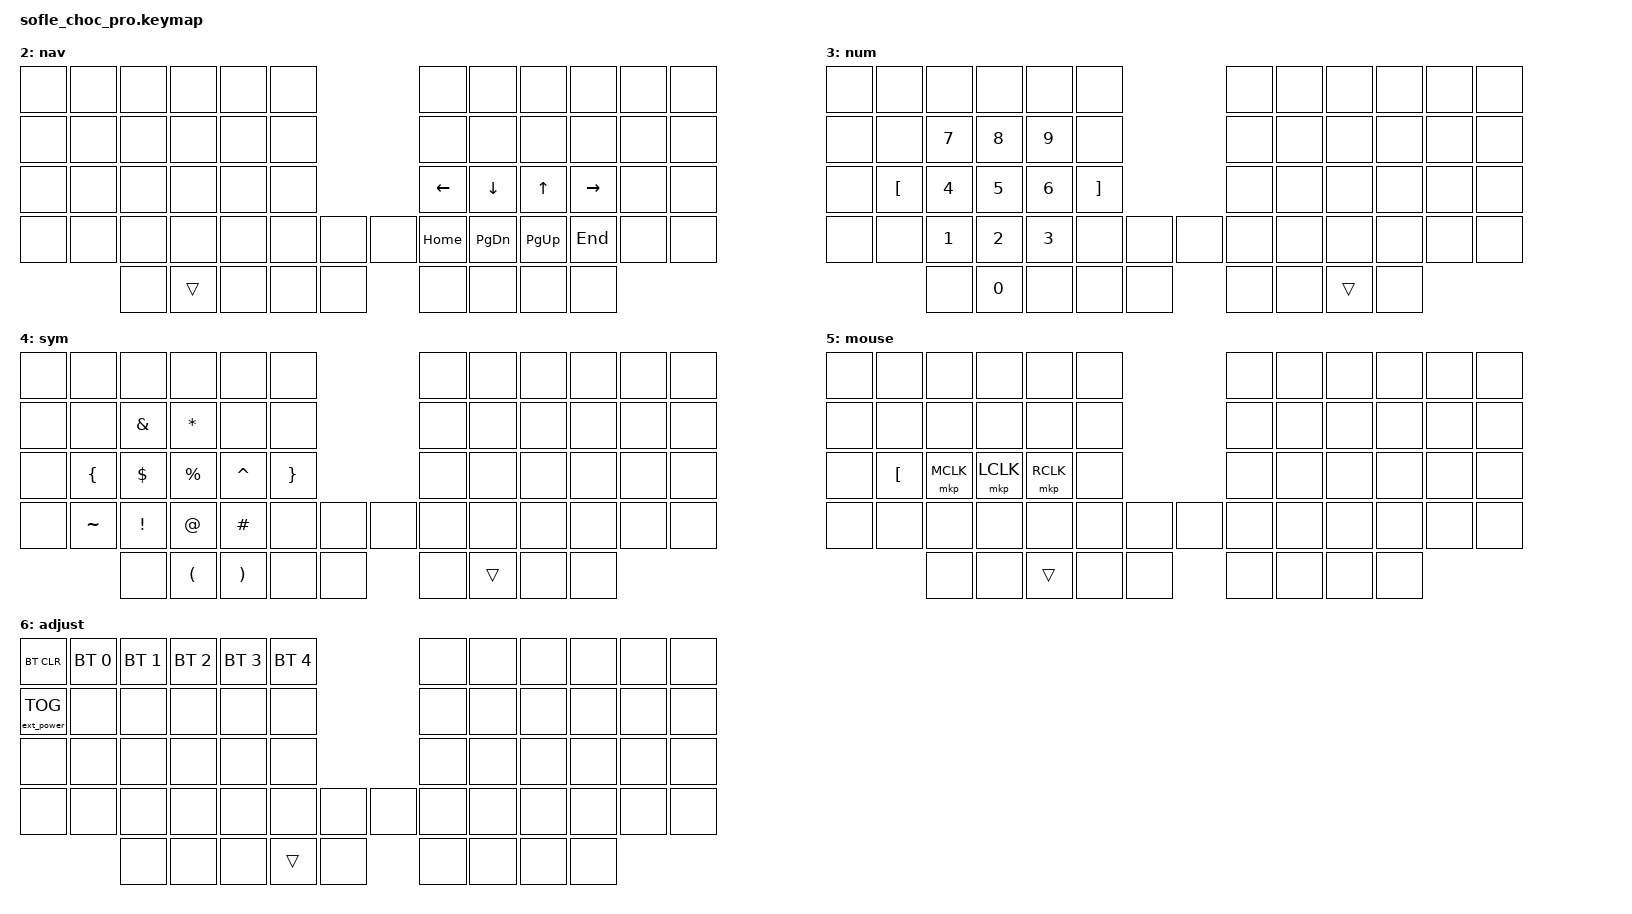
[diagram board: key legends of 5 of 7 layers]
/*
 * Sofle Choc Pro BT — ZMK Keymap
 * Exact port of QMK Dilemma keymap (casuanoob / 0xcharly)
 * Board: sofle_choc_pro_left / sofle_choc_pro_right + Prospector dongle
 *
 * Matrix: 14 columns × 5 rows = 60 keys
 *
 * Key position map (0-indexed, sequential):
 *  0  1  2  3  4  5              6  7  8  9 10 11   ← row 0 (12 keys)
 * 12 13 14 15 16 17             18 19 20 21 22 23   ← row 1 (12 keys)
 * 24 25 26 27 28 29             30 31 32 33 34 35   ← row 2 / home row (12 keys)
 * 36 37 38 39 40 41  42  43  44 45 46 47 48 49      ← row 3 (14 keys, 42+43 = center)
 *          50 51 52 53 54     55 56 57 58 59         ← row 4 / thumbs (10 keys)
 *
 * Home row positions:
 *   Left:  A=25  S=26  D=27  F=28
 *   Right: J=31  K=32  L=33  ;=34
 *
 * Combos (position-based, not keycode-based like QMK):
 *   D+F  = {27, 28} → Escape
 *   J+K  = {31, 32} → Enter
 *   F+J  = {28, 31} → CapsLock
 *
 * Thumb row (left side):  50=unused  51=NAV/BSPC  52=MOUSE/TAB  53=ADJUST  54=extra-key
 * Thumb row (right side): 55=extra-key  56=unused  57=SYM/ENT  58=NUM/SPC  59=→WIN/→MAC
 *
 * Layers:
 *   0 BASE    — Mac default, GACS home row mods
 *   1 BASEW   — Win default, SCAG home row mods
 *   2 NAV     — arrows, home/end/pgup/pgdn  (hold BSPC)
 *   3 NUM     — numpad                      (hold SPC)
 *   4 SYM     — symbols                    (hold ENT)
 *   5 MOUSE   — mouse buttons              (hold TAB)
 *   6 ADJUST  — BT management + RGB controls  (hold ADJUST thumb)
 *
 * QMK → ZMK notes:
 *   HYPR_T(KC_NO) → &trans (effectively a no-op)
 *   PT = LT(POINTER, KC_NO) → &mo ADJUST (tap = none, layer renamed to ADJUST)
 *   DPI_MOD / SNIPING / DRGSCRL → &none (Sofle has no trackball)
 *   EE_CLR → &bt BT_CLR
 *   QK_BOOT → &bootloader
 *   MS_BTNx → &mkp (ZMK pointing)
 *   Encoder keys (RC(3,6) RC(3,7)) kept as &none on non-media layers,
 *   assigned C_MUTE / C_PP on base layers to match original QMK encoder positions.
 */

#include <behaviors.dtsi>
#include <dt-bindings/zmk/keys.h>
#include <dt-bindings/zmk/bt.h>
#include <dt-bindings/zmk/mouse.h>
#include <dt-bindings/zmk/ext_power.h>

#define BASE    0
#define BASEW   1
#define NAV     2
#define NUM     3
#define SYM     4
#define MOUSE   5
#define ADJUST  6

// Key position groups for hold-trigger-key-positions
// Used to make HRMs directional: left HRMs only trigger with right-hand keys and vice versa
// Sofle Choc Pro 60-key matrix (0-indexed):
//  0  1  2  3  4  5          6  7  8  9 10 11   row 0
// 12 13 14 15 16 17         18 19 20 21 22 23   row 1
// 24 25 26 27 28 29         30 31 32 33 34 35   row 2
// 36 37 38 39 40 41  42 43  44 45 46 47 48 49   row 3
//          50 51 52 53 54   55 56 57 58 59       row 4
#define KEYS_L  0  1  2  3  4  5  12 13 14 15 16 17  24 25 26 27 28 29  36 37 38 39 40 41
#define KEYS_R  6  7  8  9 10 11  18 19 20 21 22 23  30 31 32 33 34 35  44 45 46 47 48 49
#define THUMBS 50 51 52 53 54 55 56 57 58 59
#define HYPER LS(LC(LA(LGUI)))

/ {
    // ─── Combos ───────────────────────────────────────────────────────────────
    combos {
        compatible = "zmk,combos";

        combo_esc {
            timeout-ms = <50>;
            key-positions = <27 28>;
            bindings = <&kp ESC>;
            layers = <BASE BASEW>;
        };
        combo_enter {
            timeout-ms = <50>;
            key-positions = <31 32>;
            bindings = <&kp ENTER>;
            layers = <BASE BASEW>;
        };
        combo_caps {
            timeout-ms = <50>;
            key-positions = <28 31>;
            bindings = <&kp CAPS>;
            layers = <BASE BASEW>;
        };
    };

    // ─── Macros ───────────────────────────────────────────────────────────────
    macros {
        mac_cut: mac_cut {
            compatible = "zmk,behavior-macro";
            #binding-cells = <0>;
            bindings = <&macro_press &kp LGUI>,
                       <&macro_tap &kp X>,
                       <&macro_release &kp LGUI>;
        };
        mac_copy: mac_copy {
            compatible = "zmk,behavior-macro";
            #binding-cells = <0>;
            bindings = <&macro_press &kp LGUI>,
                       <&macro_tap &kp C>,
                       <&macro_release &kp LGUI>;
        };
        mac_paste: mac_paste {
            compatible = "zmk,behavior-macro";
            #binding-cells = <0>;
            bindings = <&macro_press &kp LGUI>,
                       <&macro_tap &kp V>,
                       <&macro_release &kp LGUI>;
        };
        win_cut: win_cut {
            compatible = "zmk,behavior-macro";
            #binding-cells = <0>;
            bindings = <&macro_press &kp LCTRL>,
                       <&macro_tap &kp X>,
                       <&macro_release &kp LCTRL>;
        };
        win_copy: win_copy {
            compatible = "zmk,behavior-macro";
            #binding-cells = <0>;
            bindings = <&macro_press &kp LCTRL>,
                       <&macro_tap &kp C>,
                       <&macro_release &kp LCTRL>;
        };
        win_paste: win_paste {
            compatible = "zmk,behavior-macro";
            #binding-cells = <0>;
            bindings = <&macro_press &kp LCTRL>,
                       <&macro_tap &kp V>,
                       <&macro_release &kp LCTRL>;
        };
    };

    // ─── Behaviors ────────────────────────────────────────────────────────────
    behaviors {
        // Home row mods — directional, with prior-idle guard
        // Ported from Kinesis Advantage 360 config:
        //   - require-prior-idle-ms: won't fire mod if a key was typed within 150ms (fast typing protection)
        //   - hold-trigger-key-positions: left HRMs only fire when right-hand keys are involved and vice versa
        //   - hold-trigger-on-release: pairs with above for reliable one-shot feel
        //   - 280ms tapping term: safe to go longer because idle guard handles fast typing
        hyp: hyper {
            compatible = "zmk,behavior-hold-tap";
            #binding-cells = <2>;
            flavor              = "hold-preferred";
            tapping-term-ms     = <200>;
            bindings            = <&kp>, <&kp>;
        };        
        hml: hml {
            compatible = "zmk,behavior-hold-tap";
            #binding-cells = <2>;
            flavor                = "balanced";
            tapping-term-ms       = <280>;
            quick-tap-ms          = <175>;
            require-prior-idle-ms = <150>;
            hold-trigger-on-release;
            hold-trigger-key-positions = <KEYS_R THUMBS>;
            bindings = <&kp>, <&kp>;
        };
        hmr: hmr {
            compatible = "zmk,behavior-hold-tap";
            #binding-cells = <2>;
            flavor                = "balanced";
            tapping-term-ms       = <280>;
            quick-tap-ms          = <175>;
            require-prior-idle-ms = <150>;
            hold-trigger-on-release;
            hold-trigger-key-positions = <KEYS_L THUMBS>;
            bindings = <&kp>, <&kp>;
        };

        td_x_mac: td_x_mac {
            compatible = "zmk,behavior-tap-dance";
            #binding-cells = <0>;
            tapping-term-ms = <200>;
            bindings = <&kp X>, <&mac_cut>;
        };
        td_c_mac: td_c_mac {
            compatible = "zmk,behavior-tap-dance";
            #binding-cells = <0>;
            tapping-term-ms = <200>;
            bindings = <&kp C>, <&mac_copy>;
        };
        td_v_mac: td_v_mac {
            compatible = "zmk,behavior-tap-dance";
            #binding-cells = <0>;
            tapping-term-ms = <200>;
            bindings = <&kp V>, <&mac_paste>;
        };
        td_x_win: td_x_win {
            compatible = "zmk,behavior-tap-dance";
            #binding-cells = <0>;
            tapping-term-ms = <200>;
            bindings = <&kp X>, <&win_cut>;
        };
        td_c_win: td_c_win {
            compatible = "zmk,behavior-tap-dance";
            #binding-cells = <0>;
            tapping-term-ms = <200>;
            bindings = <&kp C>, <&win_copy>;
        };
        td_v_win: td_v_win {
            compatible = "zmk,behavior-tap-dance";
            #binding-cells = <0>;
            tapping-term-ms = <200>;
            bindings = <&kp V>, <&win_paste>;
        };
    };

    // ─── Keymap ───────────────────────────────────────────────────────────────
    keymap {
        compatible = "zmk,keymap";

        // ── BASE (Mac) ────────────────────────────────────────────────────────
        // Row 3: positions 42+43 are the two center keys (where encoders were)
        // Thumb row: 50=trans  51=NAV/BSPC  52=MOUSE/TAB  53=ADJUST  54=none
        //            55=none   56=trans      57=SYM/ENT    58=NUM/SPC  59=→WIN
        BASE_layer {
            display-name = "base";
            bindings = <
// ╭──────────┬──────────┬──────────┬──────────┬──────────┬──────────╮                         ╭──────────┬──────────┬──────────┬──────────┬──────────┬──────────╮
    &kp ESC    &none      &kp C_PREV &kp C_PP   &kp C_NEXT &kp C_MUTE                            &kp C_VOL_DN &kp C_VOL_UP &none  &none      &none      &none
// ├──────────┼──────────┼──────────┼──────────┼──────────┼──────────┤                         ├──────────┼──────────┼──────────┼──────────┼──────────┼──────────┤
    &kp EQUAL  &kp Q      &kp W      &kp E      &kp R      &kp T                                 &kp Y      &kp U      &kp I      &kp O      &kp P      &kp MINUS
// ├──────────┼──────────┼──────────┼──────────┼──────────┼──────────┤                         ├──────────┼──────────┼──────────┼──────────┼──────────┼──────────┤
    &kp LSHFT &hml LCTRL A &hml LALT S &hml LGUI D &hml LSHFT F &kp G                               &kp H  &hmr RSHFT J &hmr RGUI K &hmr RALT L &hmr RCTRL SEMI &kp SQT
// ├──────────┼──────────┼──────────┼──────────┼──────────┼──────────┼──────────┬──────────┬──────────┼──────────┼──────────┼──────────┼──────────┼──────────┤
    &kp LCTRL  &kp Z      &td_x_mac  &td_c_mac  &td_v_mac  &kp B      &kp C_MUTE  &kp C_PP  &kp N      &kp M      &kp COMMA  &kp DOT    &kp FSLH   &kp BSLH
// ╰──────────┴──────────┼──────────┼──────────┼──────────┼──────────┼──────────┴──────────┴──────────┼──────────┼──────────┼──────────┴──────────┴──────────╯
                          &mo ADJUST   &none &hyp HYPER LSHFT &lt NAV BSPC &lt MOUSE TAB                  &lt SYM ENTER &lt NUM SPACE &none &none &to BASEW
//                       ╰──────────┴──────────┴──────────┴──────────┴──────────╯          ╰──────────┴──────────┴──────────┴──────────╯
            >;
        };

        // ── BASEW (Windows) ───────────────────────────────────────────────────
        BASEW_layer {
            display-name = "win";
            bindings = <
// ╭──────────┬──────────┬──────────┬──────────┬──────────┬──────────╮                         ╭──────────┬──────────┬──────────┬──────────┬──────────┬──────────╮
    &kp ESC    &none      &kp C_PREV &kp C_PP   &kp C_NEXT &kp C_MUTE                            &kp C_VOL_DN &kp C_VOL_UP &none  &none      &none      &none
// ├──────────┼──────────┼──────────┼──────────┼──────────┼──────────┤                         ├──────────┼──────────┼──────────┼──────────┼──────────┼──────────┤
    &kp EQUAL  &kp Q      &kp W      &kp E      &kp R      &kp T                                 &kp Y      &kp U      &kp I      &kp O      &kp P      &kp MINUS
// ├──────────┼──────────┼──────────┼──────────┼──────────┼──────────┤                         ├──────────┼──────────┼──────────┼──────────┼──────────┼──────────┤
    &kp LSHFT &hml LGUI A &hml LALT S &hml LCTRL D &hml LSHFT F &kp G                               &kp H  &hmr RSHFT J &hmr RCTRL K &hmr RALT L &hmr RGUI SEMI &kp SQT
// ├──────────┼──────────┼──────────┼──────────┼──────────┼──────────┼──────────┬──────────┬──────────┼──────────┼──────────┼──────────┼──────────┼──────────┤
    &kp LCTRL  &kp Z      &td_x_win  &td_c_win  &td_v_win  &kp B      &kp C_MUTE  &kp C_PP  &kp N      &kp M      &kp COMMA  &kp DOT    &kp FSLH   &kp BSLH
// ╰──────────┴──────────┼──────────┼──────────┼──────────┼──────────┼──────────┴──────────┴──────────┼──────────┼──────────┼──────────┴──────────┴──────────╯
                          &mo ADJUST   &none &hyp HYPER LSHFT &lt NAV BSPC &lt MOUSE TAB                  &lt SYM ENTER &lt NUM SPACE &none &none &to BASE
//                       ╰──────────┴──────────┴──────────┴──────────┴──────────╯          ╰──────────┴──────────┴──────────┴──────────╯
            >;
        };

        // ── NAV ───────────────────────────────────────────────────────────────
        NAV_layer {
            display-name = "nav";
            bindings = <
// ╭──────────┬──────────┬──────────┬──────────┬──────────┬──────────╮                         ╭──────────┬──────────┬──────────┬──────────┬──────────┬──────────╮
    &none      &none      &none      &none      &none      &none                                 &none      &none      &none      &none      &none      &none
// ├──────────┼──────────┼──────────┼──────────┼──────────┼──────────┤                         ├──────────┼──────────┼──────────┼──────────┼──────────┼──────────┤
    &none      &none      &none      &none      &none      &none                                 &none      &none      &none      &none      &none      &none
// ├──────────┼──────────┼──────────┼──────────┼──────────┼──────────┤                         ├──────────┼──────────┼──────────┼──────────┼──────────┼──────────┤
    &none      &none      &none      &none      &none      &none                                 &kp LEFT   &kp DOWN   &kp UP     &kp RIGHT  &none      &none
// ├──────────┼──────────┼──────────┼──────────┼──────────┼──────────┼──────────┬──────────┬──────────┼──────────┼──────────┼──────────┼──────────┼──────────┤
    &none      &none      &none      &none      &none      &none      &none       &none      &kp HOME   &kp PG_DN  &kp PG_UP  &kp END    &none      &none
// ╰──────────┴──────────┼──────────┼──────────┼──────────┼──────────┼──────────┴──────────┴──────────┼──────────┼──────────┼──────────┴──────────┴──────────╯
                          &none      &trans     &none      &none      &none                    &none     &none      &none      &none
//                       ╰──────────┴──────────┴──────────┴──────────┴──────────╯          ╰──────────┴──────────┴──────────┴──────────╯
            >;
        };

        // ── NUM ───────────────────────────────────────────────────────────────
        NUM_layer {
            display-name = "num";
            bindings = <
// ╭──────────┬──────────┬──────────┬──────────┬──────────┬──────────╮                         ╭──────────┬──────────┬──────────┬──────────┬──────────┬──────────╮
    &none      &none      &none      &none      &none      &none                                 &none      &none      &none      &none      &none      &none
// ├──────────┼──────────┼──────────┼──────────┼──────────┼──────────┤                         ├──────────┼──────────┼──────────┼──────────┼──────────┼──────────┤
    &none      &none      &kp N7     &kp N8     &kp N9     &none                                 &none      &none      &none      &none      &none      &none
// ├──────────┼──────────┼──────────┼──────────┼──────────┼──────────┤                         ├──────────┼──────────┼──────────┼──────────┼──────────┼──────────┤
    &none      &kp LBKT   &kp N4     &kp N5     &kp N6     &kp RBKT                              &none      &none      &none      &none      &none      &none
// ├──────────┼──────────┼──────────┼──────────┼──────────┼──────────┼──────────┬──────────┬──────────┼──────────┼──────────┼──────────┼──────────┼──────────┤
    &none      &none      &kp N1     &kp N2     &kp N3     &none      &none       &none      &none      &none      &none      &none      &none      &none
// ╰──────────┴──────────┼──────────┼──────────┼──────────┼──────────┼──────────┴──────────┴──────────┼──────────┼──────────┼──────────┴──────────┴──────────╯
                          &none      &kp N0     &none      &none      &none                    &none     &none      &trans     &none
//                       ╰──────────┴──────────┴──────────┴──────────┴──────────╯          ╰──────────┴──────────┴──────────┴──────────╯
            >;
        };

        // ── SYM ───────────────────────────────────────────────────────────────
        SYM_layer {
            display-name = "sym";
            bindings = <
// ╭──────────┬──────────┬──────────┬──────────┬──────────┬──────────╮                         ╭──────────┬──────────┬──────────┬──────────┬──────────┬──────────╮
    &none      &none      &none      &none      &none      &none                                 &none      &none      &none      &none      &none      &none
// ├──────────┼──────────┼──────────┼──────────┼──────────┼──────────┤                         ├──────────┼──────────┼──────────┼──────────┼──────────┼──────────┤
    &none      &none      &kp AMPS   &kp STAR   &none      &none                                 &none      &none      &none      &none      &none      &none
// ├──────────┼──────────┼──────────┼──────────┼──────────┼──────────┤                         ├──────────┼──────────┼──────────┼──────────┼──────────┼──────────┤
    &none      &kp LBRC   &kp DLLR   &kp PRCNT  &kp CARET  &kp RBRC                              &none      &none      &none      &none      &none      &none
// ├──────────┼──────────┼──────────┼──────────┼──────────┼──────────┼──────────┬──────────┬──────────┼──────────┼──────────┼──────────┼──────────┼──────────┤
    &none      &kp TILDE  &kp EXCL   &kp AT     &kp HASH   &none      &none       &none      &none      &none      &none      &none      &none      &none
// ╰──────────┴──────────┼──────────┼──────────┼──────────┼──────────┼──────────┴──────────┴──────────┼──────────┼──────────┼──────────┴──────────┴──────────╯
                          &none      &kp LPAR   &kp RPAR   &none      &none                    &none     &trans     &none      &none
//                       ╰──────────┴──────────┴──────────┴──────────┴──────────╯          ╰──────────┴──────────┴──────────┴──────────╯
            >;
        };

        // ── MOUSE ─────────────────────────────────────────────────────────────
        MOUSE_layer {
            display-name = "mouse";
            bindings = <
// ╭──────────┬──────────┬──────────┬──────────┬──────────┬──────────╮                         ╭──────────┬──────────┬──────────┬──────────┬──────────┬──────────╮
    &none      &none      &none      &none      &none      &none                                 &none      &none      &none      &none      &none      &none
// ├──────────┼──────────┼──────────┼──────────┼──────────┼──────────┤                         ├──────────┼──────────┼──────────┼──────────┼──────────┼──────────┤
    &none      &none      &none      &none      &none      &none                                 &none      &none      &none      &none      &none      &none
// ├──────────┼──────────┼──────────┼──────────┼──────────┼──────────┤                         ├──────────┼──────────┼──────────┼──────────┼──────────┼──────────┤
    &none      &kp LBKT   &mkp MCLK  &mkp LCLK  &mkp RCLK  &none                                &none      &none      &none      &none      &none      &none
// ├──────────┼──────────┼──────────┼──────────┼──────────┼──────────┼──────────┬──────────┬──────────┼──────────┼──────────┼──────────┼──────────┼──────────┤
    &none      &none      &none      &none      &none      &none      &none       &none      &none      &none      &none      &none      &none      &none
// ╰──────────┴──────────┼──────────┼──────────┼──────────┼──────────┼──────────┴──────────┴──────────┼──────────┼──────────┼──────────┴──────────┴──────────╯
                          &none      &none      &trans     &none      &none                    &none     &none      &none      &none
//                       ╰──────────┴──────────┴──────────┴──────────┴──────────╯          ╰──────────┴──────────┴──────────┴──────────╯
            >;
        };

        // ── ADJUST — BT management, ext_power, RGB placeholders ──────────────
        // RGB bindings kept as &none since RGB is disabled (no underglow hardware
        // configured for Prospector dongle topology). Re-enable later if needed.
        ADJUST_layer {
            display-name = "adjust";
            bindings = <
// ╭──────────┬──────────┬──────────┬──────────┬──────────┬──────────╮                         ╭──────────┬──────────┬──────────┬──────────┬──────────┬──────────╮
    &bt BT_CLR &bt BT_SEL 0 &bt BT_SEL 1 &bt BT_SEL 2 &bt BT_SEL 3 &bt BT_SEL 4               &none      &none      &none      &none      &none      &none
// ├──────────┼──────────┼──────────┼──────────┼──────────┼──────────┤                         ├──────────┼──────────┼──────────┼──────────┼──────────┼──────────┤
    &ext_power EP_TOG &none &none   &none      &none      &none                                  &none      &none      &none      &none      &none      &none
// ├──────────┼──────────┼──────────┼──────────┼──────────┼──────────┤                         ├──────────┼──────────┼──────────┼──────────┼──────────┼──────────┤
    &none      &none      &none      &none      &none      &none                                  &none      &none      &none      &none      &none      &none
// ├──────────┼──────────┼──────────┼──────────┼──────────┼──────────┼──────────┬──────────┬──────────┼──────────┼──────────┼──────────┼──────────┼──────────┤
    &none      &none      &none      &none      &none      &none      &none       &none      &none      &none      &none      &none      &none      &none
// ╰──────────┴──────────┼──────────┼──────────┼──────────┼──────────┼──────────┴──────────┴──────────┼──────────┼──────────┼──────────┴──────────┴──────────╯
                          &none      &none      &none      &trans     &none                    &none     &none      &none      &none
//                       ╰──────────┴──────────┴──────────┴──────────┴──────────╯          ╰──────────┴──────────┴──────────┴──────────╯
            >;
        };
    };
};
